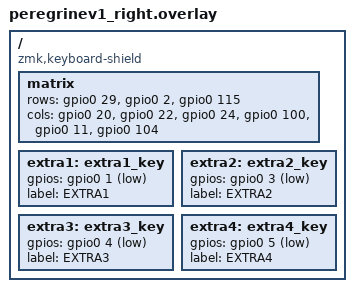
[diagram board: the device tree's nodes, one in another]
/ {
    compatible = "zmk,keyboard-shield";

    matrix {
        rows = < &gpio0 29 &gpio0 2 &gpio0 115 >;
        cols = < &gpio0 20 &gpio0 22 &gpio0 24 &gpio0 100 &gpio0 11 &gpio0 104 >;
    };

    extra1: extra1_key {
        gpios = < &gpio0 1 (GPIO_PULL_UP | GPIO_ACTIVE_LOW) >;
        label = "EXTRA1";
    };
    extra2: extra2_key {
        gpios = < &gpio0 3 (GPIO_PULL_UP | GPIO_ACTIVE_LOW) >;
        label = "EXTRA2";
    };
    extra3: extra3_key {
        gpios = < &gpio0 4 (GPIO_PULL_UP | GPIO_ACTIVE_LOW) >;
        label = "EXTRA3";
    };
    extra4: extra4_key {
        gpios = < &gpio0 5 (GPIO_PULL_UP | GPIO_ACTIVE_LOW) >;
        label = "EXTRA4";
    };
};
